# MKE14D7 register map
File version: 1.6
Registers are 32-bit, read-write, reset 0x0 unless marked. A register's access mark holds for its fields unless they carry their own. Offsets are from the block's base; [hi:lo] are bit positions; 'fields as' and 'values as' point back to an identical list.

## FTMRA — FTMRA Family Flash Module
Base 0x40039000; register names take the prefix FTMRA_
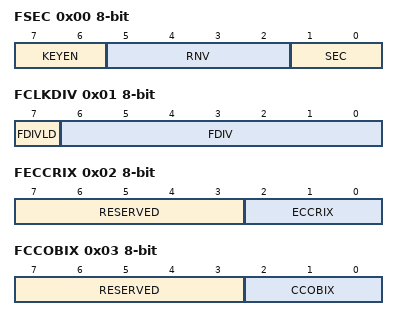
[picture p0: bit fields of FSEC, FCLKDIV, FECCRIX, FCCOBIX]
0x00 FSEC 8-bit ro reset not defined — Flash Security Register
  [7:6] KEYEN — Backdoor Key Security Enable
    0=Backdoor key access disabled; 1=Backdoor key access disabled (preferred KEYEN state to disable backdoor key access); 2=Backdoor key access enabled; 3=Backdoor key access disabled
  [5:2] RNV — Reserved Nonvolatile Bits
  [1:0] SEC — Flash Security
    0=MCU security status is secure; 1=MCU security status is secure,it is the preferred SEC state to set MCU to secured state; 2=MCU security status is unsecure; 3=MCU security status is secure
0x01 FCLKDIV 8-bit — Flash Clock Divider Register
  [7] FDIVLD ro — Clock Divider Loaded
    0=FCLKDIV register has not been written; 1=FCLKDIV register has been written since the last reset
  [6:0] FDIV — Clock Divider Bits
0x02 FECCRIX 8-bit — Flash ECCR Index Register
  [7:3] RESERVED ro
  [2:0] ECCRIX — ECC Error Register Index
0x03 FCCOBIX 8-bit — Flash Common Command Object Index Register
  [7:3] RESERVED ro
  [2:0] CCOBIX — Common Command Register Index
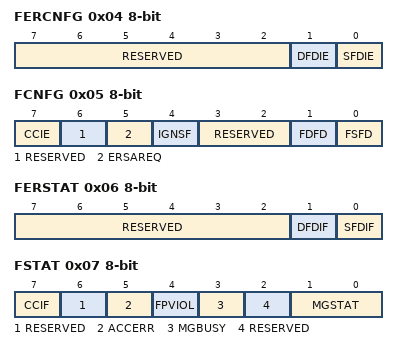
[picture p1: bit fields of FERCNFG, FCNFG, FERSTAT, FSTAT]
0x04 FERCNFG 8-bit — Flash Error Configuration Register
  [7:2] RESERVED ro
  [1] DFDIE — Double Bit Fault Detect Interrupt Enable
    0=SFDIF interrupt disabled whenever the SFDIF flag is set; 1=An interrupt will be requested whenever the SFDIF flag is set
  [0] SFDIE — Single Bit Fault Detect Interrupt Enable
    values as DFDIE
0x05 FCNFG 8-bit — Flash Configuration Register
  [7] CCIE — Command Complete Interrupt Enable
    0=Command complete interrupt disabled; 1=Command complete interrupt enabled. An interrupt request is generated whenever the FSTAT[CCIF] flag is set.
  [6] RESERVED ro
  [5] ERSAREQ ro — Erase All Request
    0=No request or request complete; 1=Request to: run the Erase All Blocks command, verify the erased state, program the security byte in the Flash Configuration Field to the unsecure state, and release MCU security by setting the FSEC[SEC] field to the unsecure state
  [4] IGNSF — Ignore Single Bit Fault
    0=All single bit faults detected during array reads are reported; 1=Single bit faults detected during array reads are not reported and the single bit fault interrupt is not generated
  [3:2] RESERVED ro
  [1] FDFD — Force Double Bit Fault Detect
    0=Flash array read operations will set the DFDIF flag in the FERSTAT register only if a double bit fault is detected; 1=Any flash array read operation will force the FERSTAT[DFDIF] flag to be set and an interrupt will be generated as long as the FERCNFG[DFDIE] is set
  [0] FSFD — Force Single Bit Fault Detect
    0=Flash array read operations will set the SFDIF flag in the FERSTAT register only if a single bit fault is detected; 1=Flash array read operation will force the SFDIF flag in the FERSTAT register to be set (see Section 1.3.2.7) and an interrupt will be generated as long as the SFDIE interrupt enable in the FERCNFG register is set
0x06 FERSTAT 8-bit — Flash Error Status Register
  [7:2] RESERVED ro
  [1] DFDIF — Double Bit Fault Detect Interrupt Flag
    0=No double bit fault detected; 1=Double bit fault detected or an invalid Flash array read operation attempted
  [0] SFDIF — Single Bit Fault Detect Interrupt Flag
    0=No single bit fault detected; 1=Single bit fault detected and corrected or an invalid Flash array read operation attempted
0x07 FSTAT 8-bit — Flash Status Register
  [7] CCIF — Command Complete Interrupt Flag
    0=Flash command in progress; 1=Flash command has completed
  [6] RESERVED ro
  [5] ACCERR — Flash Access Error Flag
    0=No access error detected; 1=Access error detected
  [4] FPVIOL — Flash Protection Violation Flag
    0=No protection violation detected; 1=Protection violation detected
  [3] MGBUSY ro — MGATE Busy Flag
    0=MGATE is idle; 1=MGATE is busy executing a Flash command (CCIF = 0)
  [2] RESERVED ro
  [1:0] MGSTAT ro — MGATE Command Completion Status Flag
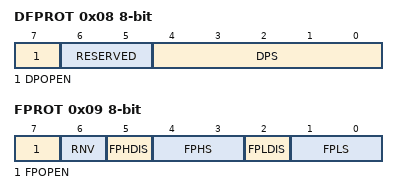
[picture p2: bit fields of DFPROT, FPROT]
0x08 DFPROT 8-bit — D-Flash Protection Register
  [7] DPOPEN — D-Flash Protection Control
    0=Enables D-Flash memory protection from program and erase with protected address range defined by DPS bits; 1=Disables D-Flash memory protection from program and erase
  [6:5] RESERVED ro
  [4:0] DPS — EraseD-Flash Protection Size
    0=Flash address range: 0x00_0000 - 0x00_00FF; protected size: 256 bytes; 1=Flash address range: 0x00_0000 - 0x00_01FF; protected size: 512 bytes; 2=Flash address range: 0x00_0000 - 0x00_02FF; protected size: 768 bytes; 3=Flash address range: 0x00_0000 - 0x00_03FF; protected size: 1024 bytes; 4=Flash address range: 0x00_0000 - 0x00_04FF; protected size: 1280 bytes; 5=Flash address range: 0x00_0000 - 0x00_05FF; protected size: 1536 bytes; 6=Flash address range: 0x00_0000 - 0x00_06FF; protected size: 1792 bytes; 7=Flash address range: 0x00_0000 - 0x00_07FF; protected size: 2048 bytes; 8=Flash address range: 0x00_0000 - 0x00_08FF; protected size: 2304 bytes; 9=Flash address range: 0x00_0000 - 0x00_09FF; protected size: 2560 bytes; 10=Flash address range: 0x00_0000 - 0x00_0AFF; protected size: 2816 bytes; 11=Flash address range: 0x00_0000 - 0x00_0BFF; protected size: 3072 bytes; 12=Flash address range: 0x00_0000 - 0x00_0CFF; protected size: 3328 bytes; 13=Flash address range: 0x00_0000 - 0x00_0DFF; protected size: 3584 bytes; 14=Flash address range: 0x00_0000 - 0x00_0EFF; protected size: 3840 bytes; 15=Flash address range: 0x00_0000 - 0x00_0FFF; protected size: 4096 bytes; 16=Flash address range: 0x00_0000 - 0x00_10FF; protected size: 4352 bytes; 17=Flash address range: 0x00_0000 - 0x00_11FF; protected size: 4608 bytes; 18=Flash address range: 0x00_0000 - 0x00_12FF; protected size: 4864 bytes; 19=Flash address range: 0x00_0000 - 0x00_13FF; protected size: 5120 bytes; 20=Flash address range: 0x00_0000 - 0x00_14FF; protected size: 5376 bytes; 21=Flash address range: 0x00_0000 - 0x00_15FF; protected size: 5632 bytes; 22=Flash address range: 0x00_0000 - 0x00_16FF; protected size: 5888 bytes; 23=Flash address range: 0x00_0000 - 0x00_17FF; protected size: 6144 bytes; 24=Flash address range: 0x00_0000 - 0x00_18FF; protected size: 6400 bytes; 25=Flash address range: 0x00_0000 - 0x00_19FF; protected size: 6656 bytes; 26=Flash address range: 0x00_0000 - 0x00_1AFF; protected size: 6912 bytes; 27=Flash address range: 0x00_0000 - 0x00_1BFF; protected size: 7168 bytes; 28=Flash address range: 0x00_0000 - 0x00_1CFF; protected size: 7424 bytes; 29=Flash address range: 0x00_0000 - 0x00_1DFF; protected size: 7680 bytes; 30=Flash address range: 0x00_0000 - 0x00_1EFF; protected size: 7936 bytes; 31=Flash address range: 0x00_0000 - 0x00_1FFF; protected size: 8192 bytes
0x09 FPROT 8-bit reset not defined — P-Flash Protection Register
  [7] FPOPEN — Flash Protection Operation Enable
    0=When FPOPEN is clear, the FPHDIS and FPLDIS bits define unprotected address ranges as specified by the corresponding FPHS and FPLS bits; 1=When FPOPEN is set, the FPHDIS and FPLDIS bits enable protection for the address range specified by the corresponding FPHS and FPLS bits
  [6] RNV ro — Reserved Nonvolatile Bit
  [5] FPHDIS — Flash Protection Higher Address Range Disable
    0=Protection/Unprotection enabled; 1=Protection/Unprotection disabled
  [4:3] FPHS — Flash Protection Higher Address Size
    0=Address range: 0x00_7C00-0x00_7FFF; protected size: 1 KB; 1=Address range: 0x00_7800-0x00_7FFF; protected size: 2 KB; 2=Address range: 0x00_7000-0x00_7FFF; protected size: 4 KB; 3=Address range: 0x00_6000-0x00_7FFF; protected size: 8 KB
  [2] FPLDIS — Flash Protection Lower Address Range Disable
    values as FPHDIS
  [1:0] FPLS — Flash Protection Lower Address Size
    0=Address range: 0x00_0000-0x00_07FF; protected size: 2 KB; 1=Address range: 0x00_0000-0x00_0FFF; protected size: 4 KB; 2=Address range: 0x00_0000-0x00_1FFF; protected size: 8 KB; 3=Address range: 0x00_0000-0x00_3FFF; protected size: 16 KB
0x0A FCCOBLO 8-bit — Flash Common Command Object Low Register
  [7:0] CCOBn
0x0B FCCOBHI 8-bit — Flash Common Command Object High Register
  [7:0] CCOBn
0x0E FECCRLO 8-bit ro — Flash ECC Error Results Low Register
  [7:0] ECCR
0x0F FECCRHI 8-bit ro — Flash ECC Error Results High Register
  [7:0] ECCR
0x11 FOPT 8-bit ro reset not defined — Flash Option Register
  [7:0] NV — Nonvolatile Bits
